# STM32U535 register map
File version: 1.7
CPU: CM33 r0p1, little endian, MPU, FPU, 4 interrupt priority bits
Registers are 32-bit, read-write, reset 0x0 unless marked. A register's access mark holds for its fields unless they carry their own. Offsets are from the block's base; [hi:lo] are bit positions; {n}, {i} and the like mark numbered series.

## ADC12_Common — Analog-to-Digital Converter
Base 0x42028300
Same registers: SEC_ADC12_Common 0x52028300
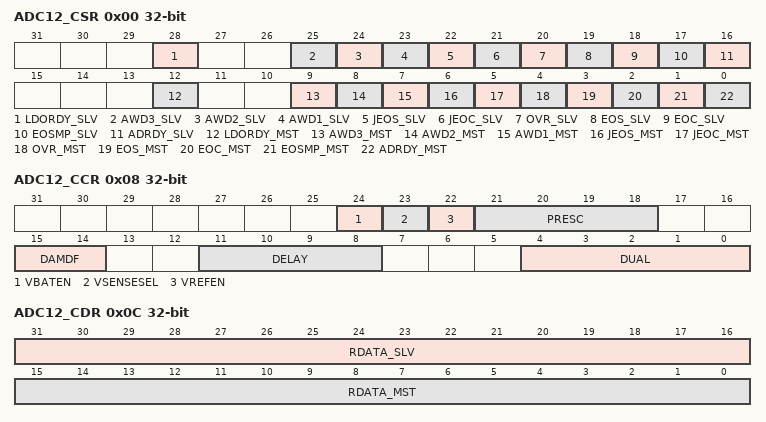
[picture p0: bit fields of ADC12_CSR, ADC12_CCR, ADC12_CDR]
0x00 ADC12_CSR ro — ADC common status register
  [28] LDORDY_SLV — ADC voltage regulator ready flag of the slave ADC
  [25] AWD3_SLV — Analog watchdog 3 flag of the slave ADC
  [24] AWD2_SLV — Analog watchdog 2 flag of the slave ADC
  [23] AWD1_SLV — Analog watchdog 1 flag of the slave ADC
  [22] JEOS_SLV — End of injected sequence flag of the slave ADC
  [21] JEOC_SLV — End of injected conversion flag of the slave ADC
  [20] OVR_SLV — Overrun flag of the slave ADC
  [19] EOS_SLV — End of regular sequence flag of the slave ADC
  [18] EOC_SLV — End of regular conversion of the slave ADC
  [17] EOSMP_SLV — End of Sampling phase flag of the slave ADC
  [16] ADRDY_SLV — Slave ADC ready
  [12] LDORDY_MST — ADC voltage regulator ready flag of the master ADC
  [9] AWD3_MST — Analog watchdog 3 flag of the master ADC
  [8] AWD2_MST — Analog watchdog 2 flag of the master ADC
  [7] AWD1_MST — Analog watchdog 1 flag of the master ADC
  [6] JEOS_MST — End of injected sequence flag of the master ADC
  [5] JEOC_MST — End of injected conversion flag of the master ADC
  [4] OVR_MST — Overrun flag of the master ADC
  [3] EOS_MST — End of regular sequence flag of the master ADC
  [2] EOC_MST — End of regular conversion of the master ADC
  [1] EOSMP_MST — End of Sampling phase flag of the master ADC
  [0] ADRDY_MST — Master ADC ready
0x08 ADC12_CCR — ADC_CCR system control register
  [24] VBATEN — VBAT enable
    0=VBAT channel disabled; 1=VBAT channel enabled
  [23] VSENSESEL — Temperature sensor voltage selection
    0=Temperature sensor channel disabled; 1=Temperature sensor channel enabled
  [22] VREFEN — VREFINT enable
    0=VREFINT channel disabled; 1=VREFINT channel enabled
  [21:18] PRESC — ADC prescaler
    0=input ADC clock not divided; 1=input ADC clock divided by 2; 2=input ADC clock divided by 4; 3=input ADC clock divided by 6; 4=input ADC clock divided by 8; 5=input ADC clock divided by 10; 6=input ADC clock divided by 12; 7=input ADC clock divided by 16; 8=input ADC clock divided by 32; 9=input ADC clock divided by 64; 10=input ADC clock divided by 128; 11=input ADC clock divided by 256
  [15:14] DAMDF — Dual ADC Mode Data Format
    0=Dual ADC mode without data packing (ADC12_CDR and ADC12_CDR2 registers not used); 2=Data formatting mode for 32 down to 10-bit resolution; 3=Data formatting mode for 8-bit resolution
  [11:8] DELAY — Delay between the end of the master ADC sampling phase and the beginning of
  [4:0] DUAL — Dual ADC mode selection
    0=Independent mode; 1=Combined regular simultaneous + injected simultaneous mode; 2=Combined regular simultaneous + alternate trigger mode; 3=Combined Interleaved mode + injected simultaneous mode; 5=Injected simultaneous mode only; 6=Regular simultaneous mode only; 7=Interleaved mode only; 9=Alternate trigger mode only
0x0C ADC12_CDR ro — ADC common regular data register for dual mode
  [31:16] RDATA_SLV — Regular data of the slave ADC
  [15:0] RDATA_MST — Regular data of the master ADC.
0x10 ADC12_CDR2 ro — ADC common regular data register for 32-bit dual mode
  [31:0] RDATA_ALT — Regular data of the master/slave alternated ADCs

## ADC4
Base 0x46021000
Same registers: SEC_ADC4 0x56021000
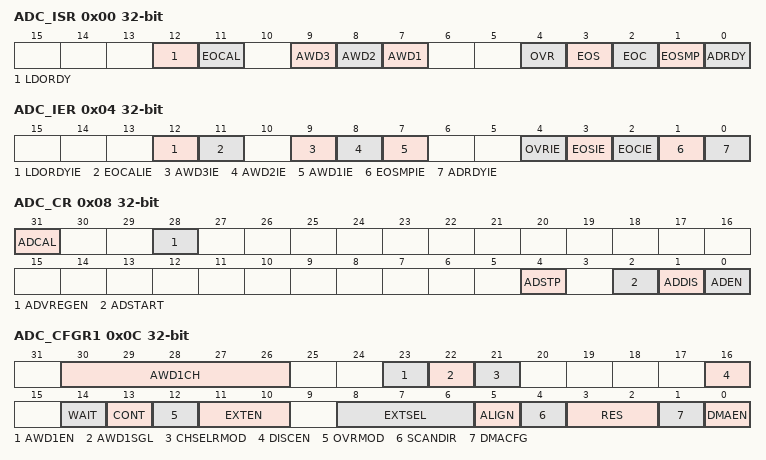
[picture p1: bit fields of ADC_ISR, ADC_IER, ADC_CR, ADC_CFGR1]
0x00 ADC_ISR — ADC interrupt and status register
  [12] LDORDY, [11] EOCAL, [9] AWD3, [8] AWD2, [7] AWD1, [4] OVR, [3] EOS, [2] EOC, [1] EOSMP, [0] ADRDY
0x04 ADC_IER — ADC interrupt enable register
  [12] LDORDYIE, [11] EOCALIE, [9] AWD3IE, [8] AWD2IE, [7] AWD1IE, [4] OVRIE, [3] EOSIE, [2] EOCIE, [1] EOSMPIE, [0] ADRDYIE
0x08 ADC_CR access per field — ADC control register
  [31] ADCAL ro, [28] ADVREGEN rw, [4] ADSTP ro, [2] ADSTART ro, [1] ADDIS ro, [0] ADEN ro
0x0C ADC_CFGR1 — ADC configuration register
  [30:26] AWD1CH, [23] AWD1EN, [22] AWD1SGL, [21] CHSELRMOD, [16] DISCEN, [14] WAIT, [13] CONT, [12] OVRMOD, [11:10] EXTEN, [8:6] EXTSEL, [5] ALIGN, [4] SCANDIR, [3:2] RES, [1] DMACFG, [0] DMAEN
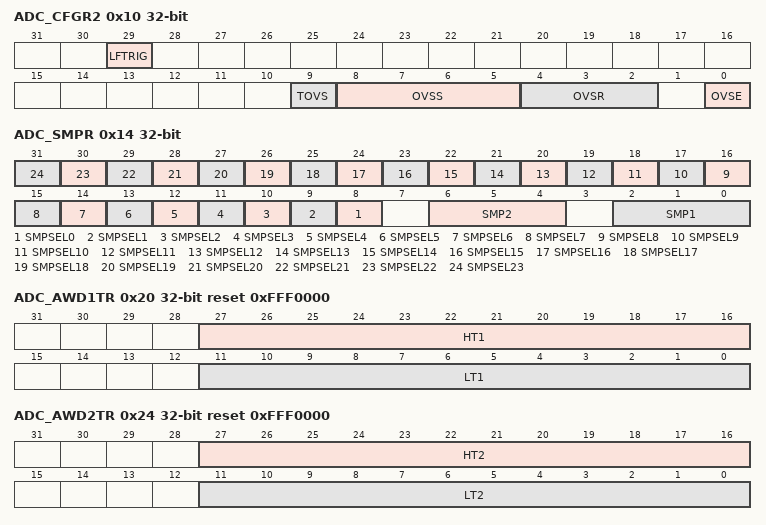
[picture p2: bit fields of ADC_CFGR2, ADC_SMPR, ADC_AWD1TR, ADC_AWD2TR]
0x10 ADC_CFGR2 — ADC configuration register 2
  [29] LFTRIG, [9] TOVS, [8:5] OVSS, [4:2] OVSR, [0] OVSE
0x14 ADC_SMPR — ADC sample time register
  [n+8] SMPSEL{n} (n=0..23), [6:4] SMP2, [2:0] SMP1
0x20 ADC_AWD1TR reset 0xFFF0000 — ADC watchdog threshold register
  [27:16] HT1, [11:0] LT1
0x24 ADC_AWD2TR reset 0xFFF0000 — ADC watchdog threshold register
  [27:16] HT2, [11:0] LT2
0x28 ADC_CHSELRMOD0 — ADC channel selection register [alternate]
  [23:0] CHSEL
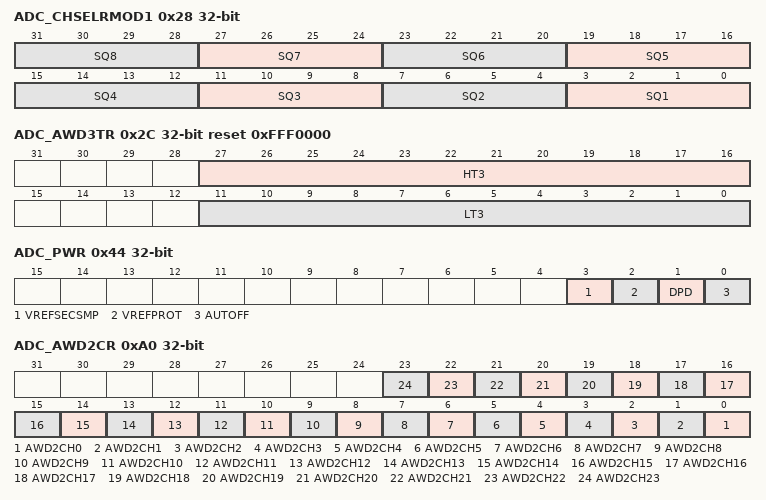
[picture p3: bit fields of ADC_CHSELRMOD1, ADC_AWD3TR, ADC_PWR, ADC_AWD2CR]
0x28 ADC_CHSELRMOD1 (alternate view of ADC_CHSELRMOD0) — ADC channel selection register [alternate]
  [4n-1:4n-4] SQ{n} (n=1..8)
0x2C ADC_AWD3TR reset 0xFFF0000 — ADC watchdog threshold register
  [27:16] HT3, [11:0] LT3
0x40 ADC_DR ro — ADC data register
  [15:0] DATA
0x44 ADC_PWR — ADC data register
  [3] VREFSECSMP, [2] VREFPROT, [1] DPD, [0] AUTOFF
0xA0 ADC_AWD2CR — ADC Analog Watchdog 2 Configuration register
  [n] AWD2CH{n} (n=0..23)
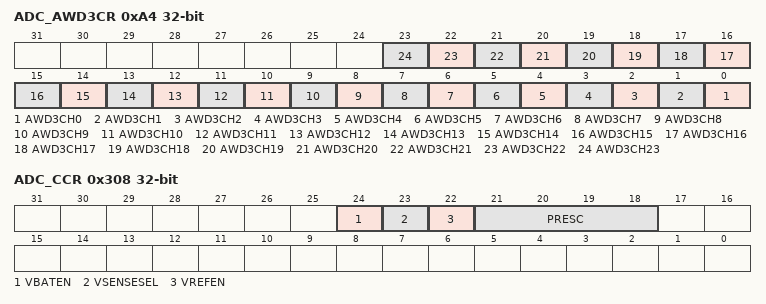
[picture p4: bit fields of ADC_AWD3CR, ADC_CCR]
0xA4 ADC_AWD3CR — ADC Analog Watchdog 3 Configuration register
  [n] AWD3CH{n} (n=0..23)
0xC4 ADC_CALFACT — ADC Calibration factor
  [6:0] CALFACT
0xD0 ADC_OR — ADC option register
  [0] CHN21SEL
0x308 ADC_CCR — ADC common configuration register
  [24] VBATEN, [23] VSENSESEL, [22] VREFEN, [21:18] PRESC

## Notices in the file
Copyright (c) 2025 STMicroelectronics.
SPDX-License-Identifier: Apache-2.0
Licensed under the Apache License, Version 2.0 (the "License");
you may not use this file except in compliance with the License.
You may obtain a copy of the License at
http://www.apache.org/licenses/LICENSE-2.0
Unless required by applicable law or agreed to in writing, software
distributed under the License is distributed on an "AS IS" BASIS,
WITHOUT WARRANTIES OR CONDITIONS OF ANY KIND, either express or implied.
See the License for the specific language governing permissions and
limitations under the License.
